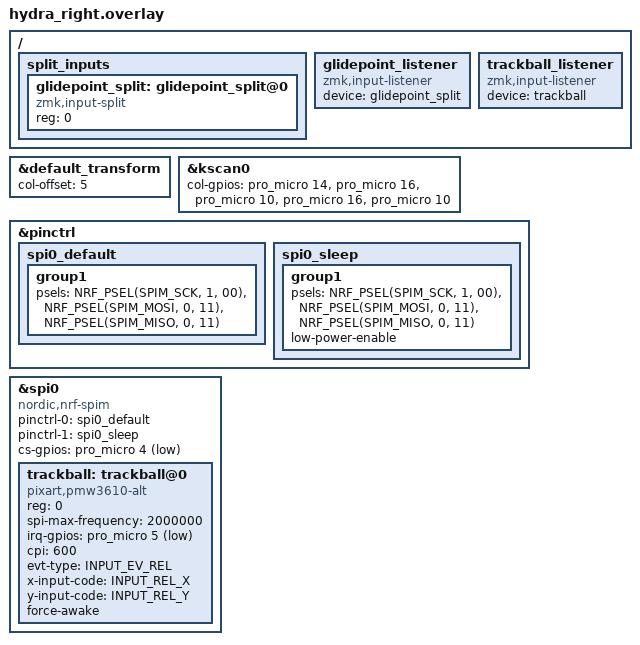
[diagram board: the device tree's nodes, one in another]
#include "hydra.dtsi"
#include <zephyr/dt-bindings/input/input-event-codes.h>

&default_transform { col-offset = <5>; };

&kscan0 {
    col-gpios
        = <&pro_micro 14 GPIO_ACTIVE_HIGH> // COL1 D14
        , <&pro_micro 16 GPIO_ACTIVE_HIGH> // COL2 D16
        , <&pro_micro 10 GPIO_ACTIVE_HIGH> // COL3 D10
        , <&pro_micro 16 GPIO_ACTIVE_HIGH> // COL4 TBD
        , <&pro_micro 10 GPIO_ACTIVE_HIGH> // COL5 TBD
        ;
};

&pinctrl {
    spi0_default: spi0_default {
        group1 {
            psels = <NRF_PSEL(SPIM_SCK, 1, 00)>,   // D6
                <NRF_PSEL(SPIM_MOSI, 0, 11)>,       // D7
                <NRF_PSEL(SPIM_MISO, 0, 11)>;       // D7 3-wire
        };
    };
    spi0_sleep: spi0_sleep {
        group1 {
            psels = <NRF_PSEL(SPIM_SCK, 1, 00)>,   // D6
                <NRF_PSEL(SPIM_MOSI, 0, 11)>,       // D7
                <NRF_PSEL(SPIM_MISO, 0, 11)>;       // D7 3-wire
            low-power-enable;
        };
    };
};

&spi0 {
    status = "okay";
    compatible = "nordic,nrf-spim";
    pinctrl-0 = <&spi0_default>;
    pinctrl-1 = <&spi0_sleep>;
    pinctrl-names = "default", "sleep";
    cs-gpios = <&pro_micro 4 GPIO_ACTIVE_LOW>; // D4 = NCS

    trackball: trackball@0 {
        compatible = "pixart,pmw3610-alt";
        status = "okay";
        reg = <0>;
        spi-max-frequency = <2000000>;
        irq-gpios = <&pro_micro 5 (GPIO_ACTIVE_LOW | GPIO_PULL_UP)>; // D5 = MOT
        cpi = <600>;
        evt-type = <INPUT_EV_REL>;
        x-input-code = <INPUT_REL_X>;
        y-input-code = <INPUT_REL_Y>;
        force-awake;
    };
};

/ {
    split_inputs {
        #address-cells = <1>;
        #size-cells = <0>;
        glidepoint_split: glidepoint_split@0 {
            compatible = "zmk,input-split";
            reg = <0>;
        };
    };
    glidepoint_listener: glidepoint_listener {
        compatible = "zmk,input-listener";
        device = <&glidepoint_split>;
    };
    trackball_listener: trackball_listener {
        compatible = "zmk,input-listener";
        device = <&trackball>;
    };
};
